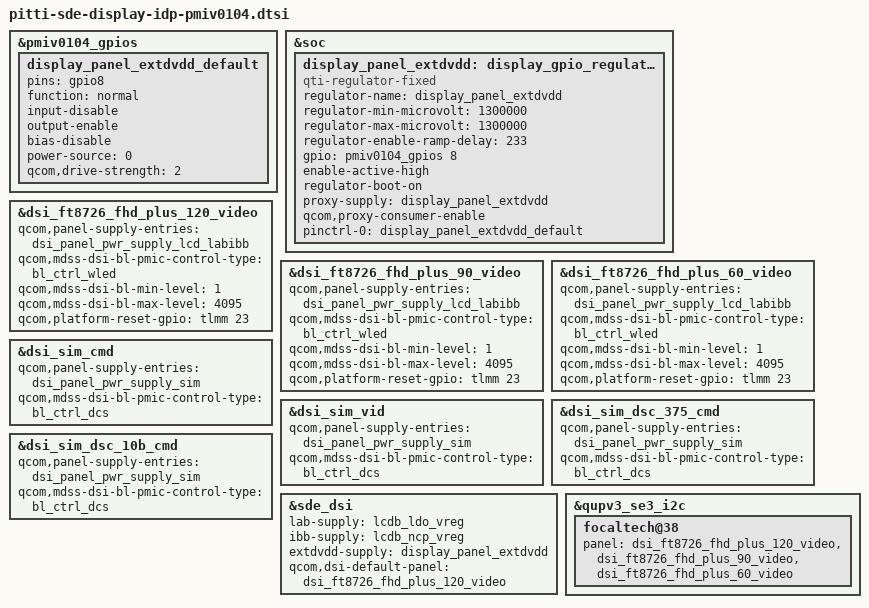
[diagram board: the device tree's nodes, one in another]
#include "pitti-sde-display.dtsi"

&pmiv0104_gpios {
	display_panel_extdvdd_default: display_panel_extdvdd_default {
		pins = "gpio8";
		function = "normal";
		input-disable;
		output-enable;
		bias-disable;
		power-source = <0>;
		qcom,drive-strength = <2>;
	};
};

&soc {
	display_panel_extdvdd: display_gpio_regulator@2 {
		compatible = "qti-regulator-fixed";
		regulator-name = "display_panel_extdvdd";
		regulator-min-microvolt = <1300000>;
		regulator-max-microvolt = <1300000>;
		regulator-enable-ramp-delay = <233>;
		gpio = <&pmiv0104_gpios 8 0>;
		enable-active-high;
		regulator-boot-on;
		proxy-supply = <&display_panel_extdvdd>;
		qcom,proxy-consumer-enable;
		pinctrl-names = "default";
		pinctrl-0 = <&display_panel_extdvdd_default>;
	};
};

&dsi_ft8726_fhd_plus_120_video {
	qcom,panel-supply-entries = <&dsi_panel_pwr_supply_lcd_labibb>;
	qcom,mdss-dsi-bl-pmic-control-type = "bl_ctrl_wled";
	qcom,mdss-dsi-bl-min-level = <1>;
	qcom,mdss-dsi-bl-max-level = <4095>;
	qcom,platform-reset-gpio = <&tlmm 23 0>;
};

&dsi_ft8726_fhd_plus_90_video {
	qcom,panel-supply-entries = <&dsi_panel_pwr_supply_lcd_labibb>;
	qcom,mdss-dsi-bl-pmic-control-type = "bl_ctrl_wled";
	qcom,mdss-dsi-bl-min-level = <1>;
	qcom,mdss-dsi-bl-max-level = <4095>;
	qcom,platform-reset-gpio = <&tlmm 23 0>;
};

&dsi_ft8726_fhd_plus_60_video {
	qcom,panel-supply-entries = <&dsi_panel_pwr_supply_lcd_labibb>;
	qcom,mdss-dsi-bl-pmic-control-type = "bl_ctrl_wled";
	qcom,mdss-dsi-bl-min-level = <1>;
	qcom,mdss-dsi-bl-max-level = <4095>;
	qcom,platform-reset-gpio = <&tlmm 23 0>;
};

&dsi_sim_cmd {
	qcom,panel-supply-entries = <&dsi_panel_pwr_supply_sim>;
	qcom,mdss-dsi-bl-pmic-control-type = "bl_ctrl_dcs";
};

&dsi_sim_vid {
	qcom,panel-supply-entries = <&dsi_panel_pwr_supply_sim>;
	qcom,mdss-dsi-bl-pmic-control-type = "bl_ctrl_dcs";
};

&dsi_sim_dsc_375_cmd {
	qcom,panel-supply-entries = <&dsi_panel_pwr_supply_sim>;
	qcom,mdss-dsi-bl-pmic-control-type = "bl_ctrl_dcs";
};

&dsi_sim_dsc_10b_cmd {
	qcom,panel-supply-entries = <&dsi_panel_pwr_supply_sim>;
	qcom,mdss-dsi-bl-pmic-control-type = "bl_ctrl_dcs";
};

&sde_dsi {
	lab-supply = <&lcdb_ldo_vreg>;
	ibb-supply = <&lcdb_ncp_vreg>;
	extdvdd-supply = <&display_panel_extdvdd>;

	qcom,dsi-default-panel = <&dsi_ft8726_fhd_plus_120_video>;
};

&qupv3_se3_i2c {
	focaltech@38 {
		panel = <&dsi_ft8726_fhd_plus_120_video
			&dsi_ft8726_fhd_plus_90_video
			&dsi_ft8726_fhd_plus_60_video>;
	};
};
